AUTOSAR XML (schema 4-3-0)
package /Actuators_Comp
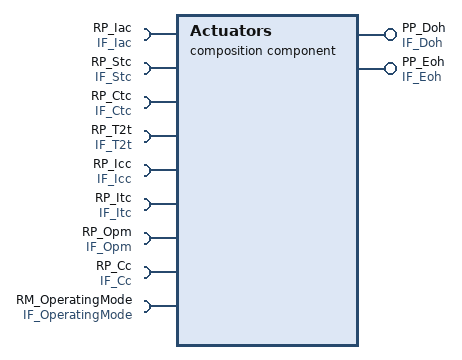
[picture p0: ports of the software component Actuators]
  composition sw component type Actuators
    4 x require port:
      RP_Iac: required-interface=IF_Iac
      RP_Stc: required-interface=IF_Stc
      RP_Ctc: required-interface=IF_Ctc
      RP_T2t: required-interface=IF_T2t
    provide port PP_Doh: provided-interface=IF_Doh
    require port RP_Icc: required-interface=IF_Icc
    provide port PP_Eoh: provided-interface=IF_Eoh
    4 x require port:
      RP_Itc: required-interface=IF_Itc
      RP_Opm: required-interface=IF_Opm
      RP_Cc: required-interface=IF_Cc
      RM_OperatingMode: required-interface=IF_OperatingMode
    15 x component:
      CPT_Eoh: type=Eoh
      CPT_Doh: type=Doh
      CPT_Str: type=Str
      CPT_Cov: type=Cov
      CPT_Ais: type=Ais
      CPT_Apv: type=Apv
      CPT_Ics: type=Ics
      CPT_Wgc: type=Wgc
      CPT_Wcs: type=Wcs
      CPT_Ivc: type=Ivc
      CPT_Fps: type=Fps
      CPT_Igc: type=Igc
      CPT_Mrs: type=Mrs
      CPT_Tvc: type=Tvc
      CPT_TvcActuator: type=TvcActuator
    connect CPT_Str.PP_Str -> CPT_Doh.RP_Str
    connect CPT_Ics.PP_Ics -> CPT_Eoh.RP_Ics
    connect CPT_Ais.PP_Ais -> CPT_Doh.RP_Ais
    connect CPT_Tvc.PP_Tvc -> CPT_Doh.RP_Tvc
    connect CPT_Str.PP_Str -> CPT_Eoh.RP_Str
    connect CPT_Cov.PP_Cov -> CPT_Doh.RP_Cov
    connect CPT_Wcs.PP_Wcs -> CPT_Doh.RP_Wcs
    connect CPT_Apv.PP_Apv -> CPT_Doh.RP_Apv
    connect CPT_Fps.PP_Fps -> CPT_Doh.RP_Fps
    connect CPT_Ics.PP_Ics -> CPT_Doh.RP_Ics
    connect CPT_Ais.PP_Ais -> CPT_Eoh.RP_Ais
    connect CPT_Fps.PP_Fps -> CPT_Eoh.RP_Fps
    connect CPT_Tvc.PP_Tvc -> CPT_Eoh.RP_Tvc
    connect CPT_Cov.PP_Cov -> CPT_Eoh.RP_Cov
    connect CPT_Apv.PP_Apv -> CPT_Eoh.RP_Apv
    connect CPT_Ivc.PP_Ivc -> CPT_Eoh.RP_Ivc
    connect CPT_Wcs.PP_Wcs -> CPT_Eoh.RP_Wcs
    connect CPT_Wgc.PP_Wgc -> CPT_Doh.RP_Wgc
    delegate CPT_Igc.RP_Iac <-> outer port Actuators/RP_Iac
    delegate CPT_Str.RP_Stc <-> outer port Actuators/RP_Stc
    delegate CPT_Wcs.RP_Ctc <-> outer port Actuators/RP_Ctc
    delegate CPT_Wgc.RP_T2t <-> outer port Actuators/RP_T2t
    delegate CPT_Doh.PP_Doh <-> outer port Actuators/PP_Doh
    delegate CPT_Eoh.RP_Icc <-> outer port Actuators/RP_Icc
    delegate CPT_Eoh.PP_Eoh <-> outer port Actuators/PP_Eoh
    delegate CPT_Ivc.RP_Itc <-> outer port Actuators/RP_Itc
    connect CPT_Mrs.PP_Mrs -> CPT_Eoh.RP_Mrs
    connect CPT_Mrs.PP_Mrs -> CPT_Doh.RP_Mrs
    delegate CPT_Eoh.RP_Stc <-> outer port Actuators/RP_Stc
    delegate CPT_Cov.RP_Opm <-> outer port Actuators/RP_Opm
    delegate CPT_Cov.RP_Cc <-> outer port Actuators/RP_Cc
    delegate CPT_Ics.RP_Opm <-> outer port Actuators/RP_Opm
    delegate CPT_Tvc.RP_Opm <-> outer port Actuators/RP_Opm
    delegate CPT_Fps.RP_Cc <-> outer port Actuators/RP_Cc
    delegate CPT_Str.RP_Opm <-> outer port Actuators/RP_Opm
    delegate CPT_Wgc.RP_Opm <-> outer port Actuators/RP_Opm
    delegate CPT_Ais.RP_Opm <-> outer port Actuators/RP_Opm
    delegate CPT_Tvc.RP_Cc <-> outer port Actuators/RP_Cc
    delegate CPT_Mrs.RP_Opm <-> outer port Actuators/RP_Opm
    delegate CPT_Apv.RP_Cc <-> outer port Actuators/RP_Cc
    delegate CPT_Fps.RP_Opm <-> outer port Actuators/RP_Opm
    delegate CPT_Ics.RP_Cc <-> outer port Actuators/RP_Cc
    delegate CPT_Ivc.RP_Cc <-> outer port Actuators/RP_Cc
    delegate CPT_Apv.RP_Opm <-> outer port Actuators/RP_Opm
    delegate CPT_Wcs.RP_Opm <-> outer port Actuators/RP_Opm
    delegate CPT_Mrs.RP_Cc <-> outer port Actuators/RP_Cc
    delegate CPT_Ais.RP_Cc <-> outer port Actuators/RP_Cc
    delegate CPT_Igc.RP_Cc <-> outer port Actuators/RP_Cc
    connect CPT_Igc.PP_Igc -> CPT_Eoh.RP_Igc
    connect CPT_TvcActuator.SP_Tvc -> CPT_Tvc.CP_Tvc
    delegate CPT_Tvc.RM_OperatingMode <-> outer port Actuators/RM_OperatingMode
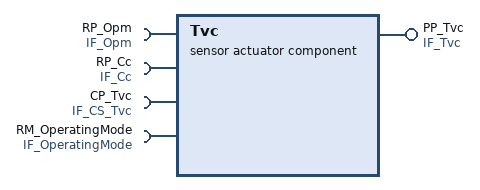
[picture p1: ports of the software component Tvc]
  sensor actuator sw component type Tvc
    provide port PP_Tvc: provided-interface=IF_Tvc
    4 x require port:
      RP_Opm: required-interface=IF_Opm
      RP_Cc: required-interface=IF_Cc
      CP_Tvc: required-interface=IF_CS_Tvc
      RM_OperatingMode: required-interface=IF_OperatingMode
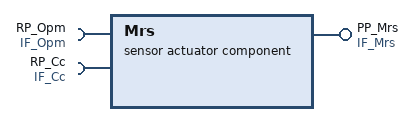
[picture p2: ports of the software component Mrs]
  sensor actuator sw component type Mrs
    require port RP_Opm: required-interface=IF_Opm
    require port RP_Cc: required-interface=IF_Cc
    provide port PP_Mrs: provided-interface=IF_Mrs
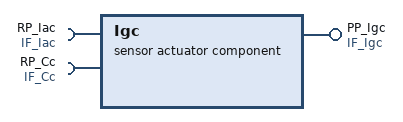
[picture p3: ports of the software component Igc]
  sensor actuator sw component type Igc
    provide port PP_Igc: provided-interface=IF_Igc
    require port RP_Iac: required-interface=IF_Iac
    require port RP_Cc: required-interface=IF_Cc
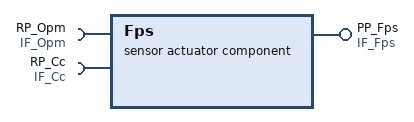
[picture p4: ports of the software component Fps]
  sensor actuator sw component type Fps
    provide port PP_Fps: provided-interface=IF_Fps
    require port RP_Opm: required-interface=IF_Opm
    require port RP_Cc: required-interface=IF_Cc
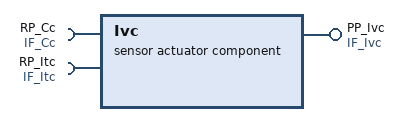
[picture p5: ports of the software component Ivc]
  sensor actuator sw component type Ivc
    provide port PP_Ivc: provided-interface=IF_Ivc
    require port RP_Cc: required-interface=IF_Cc
    require port RP_Itc: required-interface=IF_Itc
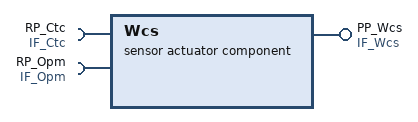
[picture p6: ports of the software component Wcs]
  sensor actuator sw component type Wcs
    provide port PP_Wcs: provided-interface=IF_Wcs
    require port RP_Ctc: required-interface=IF_Ctc
    require port RP_Opm: required-interface=IF_Opm
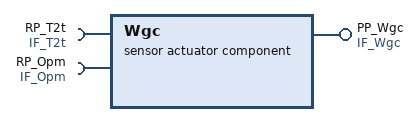
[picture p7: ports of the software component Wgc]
  sensor actuator sw component type Wgc
    require port RP_T2t: required-interface=IF_T2t
    require port RP_Opm: required-interface=IF_Opm
    provide port PP_Wgc: provided-interface=IF_Wgc
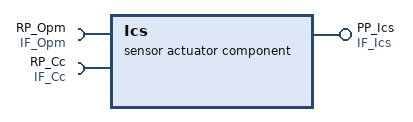
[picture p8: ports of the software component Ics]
  sensor actuator sw component type Ics
    provide port PP_Ics: provided-interface=IF_Ics
    require port RP_Opm: required-interface=IF_Opm
    require port RP_Cc: required-interface=IF_Cc
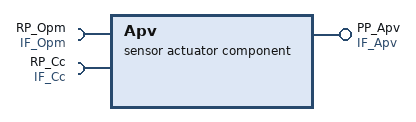
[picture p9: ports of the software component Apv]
  sensor actuator sw component type Apv
    provide port PP_Apv: provided-interface=IF_Apv
    require port RP_Opm: required-interface=IF_Opm
    require port RP_Cc: required-interface=IF_Cc
  sensor actuator sw component type Ais
    provide port PP_Ais: provided-interface=IF_Ais
    require port RP_Opm: required-interface=IF_Opm
    require port RP_Cc: required-interface=IF_Cc
  sensor actuator sw component type Cov
    provide port PP_Cov: provided-interface=IF_Cov
    require port RP_Opm: required-interface=IF_Opm
    require port RP_Cc: required-interface=IF_Cc
  sensor actuator sw component type Str
    provide port PP_Str: provided-interface=IF_Str
    require port RP_Stc: required-interface=IF_Stc
    require port RP_Opm: required-interface=IF_Opm
  application sw component type Doh
    provide port PP_Doh: provided-interface=IF_Doh
    10 x require port:
      RP_Tvc: required-interface=IF_Tvc
      RP_Mrs: required-interface=IF_Mrs
      RP_Fps: required-interface=IF_Fps
      RP_Wcs: required-interface=IF_Wcs
      RP_Wgc: required-interface=IF_Wgc
      RP_Apv: required-interface=IF_Apv
      RP_Ais: required-interface=IF_Ais
      RP_Cov: required-interface=IF_Cov
      RP_Str: required-interface=IF_Str
      RP_Ics: required-interface=IF_Ics
  application sw component type Eoh
    provide port PP_Eoh: provided-interface=IF_Eoh
    13 x require port:
      RP_Stc: required-interface=IF_Stc
      RP_Icc: required-interface=IF_Icc
      RP_Tvc: required-interface=IF_Tvc
      RP_Mrs: required-interface=IF_Mrs
      RP_Fps: required-interface=IF_Fps
      RP_Ivc: required-interface=IF_Ivc
      RP_Wcs: required-interface=IF_Wcs
      RP_Apv: required-interface=IF_Apv
      RP_Ais: required-interface=IF_Ais
      RP_Cov: required-interface=IF_Cov
      RP_Str: required-interface=IF_Str
      RP_Ics: required-interface=IF_Ics
      RP_Igc: required-interface=IF_Igc
package /Actuators_Comp/PortInterfaceMappingSets
  port interface mapping set PIMSet_Actuators
